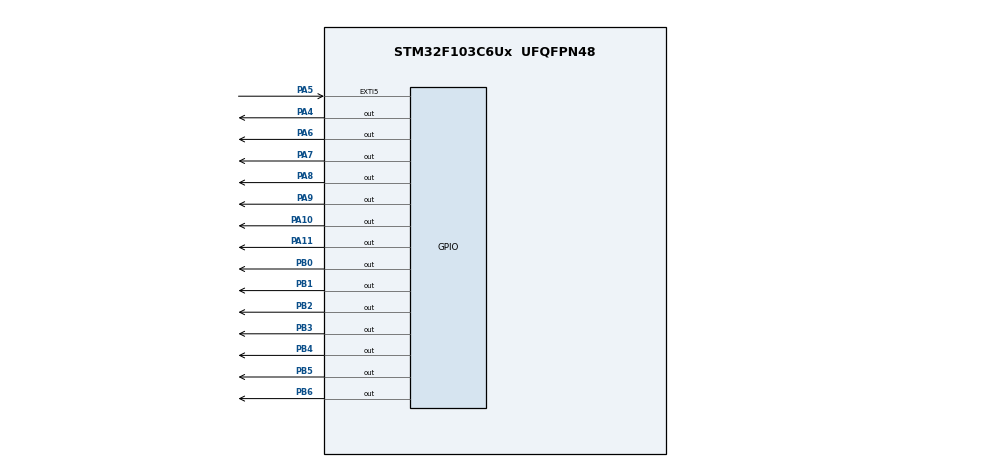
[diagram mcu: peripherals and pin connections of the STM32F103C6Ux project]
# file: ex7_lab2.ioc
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Mcu.Family=STM32F1
Mcu.Name=STM32F103C6Ux
Mcu.Package=UFQFPN48
NVIC.PriorityGroup=NVIC_PRIORITYGROUP_4
NVIC.TIM2_IRQn=true\:0\:0\:false\:false\:true\:true\:true
PA10.Signal=GPIO_Output
PA11.Signal=GPIO_Output
PA4.Signal=GPIO_Output
PA5.Signal=GPXTI5
PA6.Signal=GPIO_Output
PA7.Signal=GPIO_Output
PA8.Signal=GPIO_Output
PA9.Signal=GPIO_Output
PB0.Signal=GPIO_Output
PB1.Signal=GPIO_Output
PB2.Signal=GPIO_Output
PB3.Signal=GPIO_Output
PB4.Signal=GPIO_Output
PB5.Signal=GPIO_Output
PB6.Signal=GPIO_Output
ProjectManager.HeapSize=0x200
ProjectManager.StackSize=0x400
ProjectManager.TargetToolchain=STM32CubeIDE
RCC.APB1Freq_Value=8000000
RCC.APB2Freq_Value=8000000
TIM2.Period=9
TIM2.Prescaler=799
VP_SYS_VS_ND.Mode=No_Debug
VP_TIM2_VS_ClockSourceINT.Mode=Internal
board=custom

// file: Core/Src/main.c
/* USER CODE BEGIN Header */
/**
 ******************************************************************************
 * @file           : main.c
 * @brief          : Main program body
 ******************************************************************************
 * @attention
 *
 * <h2><center>&copy; Copyright (c) 2024 STMicroelectronics.
 * All rights reserved.</center></h2>
 *
 * This software component is licensed by ST under BSD 3-Clause license,
 * the "License"; You may not use this file except in compliance with the
 * License. You may obtain a copy of the License at:
 *                        opensource.org/licenses/BSD-3-Clause
 *
 ******************************************************************************
 */
/* USER CODE END Header */
#include "main.h"
int clockCounter = 50;
int dotCounter = 10;
int indexLed = 0;
int maxLedNum = 6;
int led_buffer[6];
int hour = 15, minute = 50, second = 0;
int zero[6] = { 0, 1, 2, 3, 4, 5 };
int one[2] = { 1, 2 };
int two[5] = { 0, 1, 6, 4, 3 };
int three[5] = { 0, 1, 6, 2, 3 };
int four[4] = { 5, 6, 1, 2 };
int five[5] = { 0, 5, 6, 2, 3 };
int six[6] = { 0, 5, 6, 2, 3, 4 };
int seven[3] = { 0, 1, 2 };
int eight[7] = { 0, 1, 2, 3, 4, 5, 6 };
int nine[6] = { 0, 1, 2, 3, 5, 6 };

int timer0_counter = 1;
int timer1_counter = 0;
int timer2_counter = 0;
int timer0_flag = 0;
int timer1_flag = 0;
int timer2_flag = 0;
int TIMER_CYCLE = 10;
void setTimer0(int duration) {
	timer0_counter = duration / TIMER_CYCLE;
	timer0_flag = 0;
}
void setTimer1(int duration) {
	timer1_counter = duration / TIMER_CYCLE;
	timer1_flag = 0;
}
void setTimer2(int duration) {
	timer2_counter = duration / TIMER_CYCLE;
	timer2_flag = 0;
}
void timer0_run() {
	if (timer0_counter > 0) {
		timer0_counter--;
		if (timer0_counter == 0) {
			timer0_flag = 1;
		}
	}

}
void timer1_run() {

	if (timer1_counter > 0) {
		timer1_counter--;
		if (timer1_counter == 0) {
			timer1_flag = 1;
		}
	}

}
void timer2_run() {

	if (timer2_counter > 0) {
		timer2_counter--;
		if (timer2_counter == 0) {
			timer2_flag = 1;
		}
	}
}
void display_7_SEG(int num) {
	for (int a = 0; a < 7; a++) {
		uint16_t b = a;
		HAL_GPIO_WritePin(GPIOB, (uint16_t) (1 << b), GPIO_PIN_SET);

	}
	switch (num) {

	case 0:
		for (int a = 0; a < sizeof(zero) / sizeof(*zero); a++) {
			uint16_t b = zero[a];
			HAL_GPIO_WritePin(GPIOB, (uint16_t) (1 << b), GPIO_PIN_RESET);
		}
		break;
	case 1:
		for (int a = 0; a < sizeof(one) / sizeof(*one); a++) {
			uint16_t b = one[a];
			HAL_GPIO_WritePin(GPIOB, (uint16_t) (1 << b), GPIO_PIN_RESET);
		}
		break;
	case 2:
		for (int a = 0; a < sizeof(two) / sizeof(*two); a++) {
			uint16_t b = two[a];
			HAL_GPIO_WritePin(GPIOB, (uint16_t) (1 << b), GPIO_PIN_RESET);
		}
		break;
	case 3:
		for (int a = 0; a < sizeof(three) / sizeof(*three); a++) {
			uint16_t b = three[a];
			HAL_GPIO_WritePin(GPIOB, (uint16_t) (1 << b), GPIO_PIN_RESET);
		}
		break;
	case 4:
		for (int a = 0; a < sizeof(four) / sizeof(*four); a++) {
			uint16_t b = four[a];
			HAL_GPIO_WritePin(GPIOB, (uint16_t) (1 << b), GPIO_PIN_RESET);
		}
		break;
	case 5:
		for (int a = 0; a < sizeof(five) / sizeof(*five); a++) {
			uint16_t b = five[a];
			HAL_GPIO_WritePin(GPIOB, (uint16_t) (1 << b), GPIO_PIN_RESET);
		}
		break;
	case 6:
		for (int a = 0; a < sizeof(six) / sizeof(*six); a++) {
			uint16_t b = six[a];
			HAL_GPIO_WritePin(GPIOB, (uint16_t) (1 << b), GPIO_PIN_RESET);
		}
		break;
	case 7:
		for (int a = 0; a < sizeof(seven) / sizeof(*seven); a++) {
			uint16_t b = seven[a];
			HAL_GPIO_WritePin(GPIOB, (uint16_t) (1 << b), GPIO_PIN_RESET);
		}
		break;
	case 8:
		for (int a = 0; a < sizeof(eight) / sizeof(*eight); a++) {
			uint16_t b = eight[a];
			HAL_GPIO_WritePin(GPIOB, (uint16_t) (1 << b), GPIO_PIN_RESET);
		}
		break;
	case 9:
		for (int a = 0; a < sizeof(nine) / sizeof(*nine); a++) {
			uint16_t b = nine[a];
			HAL_GPIO_WritePin(GPIOB, (uint16_t) (1 << b), GPIO_PIN_RESET);
		}
		break;

	}

}
void update7SEG(int index) {
	switch (index) {
	case 0:
		HAL_GPIO_WritePin(GPIOA, GPIO_PIN_6, GPIO_PIN_RESET);
		HAL_GPIO_WritePin(GPIOA,
		GPIO_PIN_7 | GPIO_PIN_8 | GPIO_PIN_9 | GPIO_PIN_10 | GPIO_PIN_11,
				GPIO_PIN_SET);
		display_7_SEG(led_buffer[0]);
		break;
	case 1:
		HAL_GPIO_WritePin(GPIOA, GPIO_PIN_7, GPIO_PIN_RESET);
		HAL_GPIO_WritePin(GPIOA,
		GPIO_PIN_6 | GPIO_PIN_8 | GPIO_PIN_9 | GPIO_PIN_10 | GPIO_PIN_11,
				GPIO_PIN_SET);
		display_7_SEG(led_buffer[1]);
		break;
	case 2:
		HAL_GPIO_WritePin(GPIOA, GPIO_PIN_8, GPIO_PIN_RESET);
		HAL_GPIO_WritePin(GPIOA,
		GPIO_PIN_6 | GPIO_PIN_7 | GPIO_PIN_9 | GPIO_PIN_10 | GPIO_PIN_11,
				GPIO_PIN_SET);
		display_7_SEG(led_buffer[2]);
		break;
	case 3:
		HAL_GPIO_WritePin(GPIOA, GPIO_PIN_9, GPIO_PIN_RESET);
		HAL_GPIO_WritePin(GPIOA,
		GPIO_PIN_6 | GPIO_PIN_7 | GPIO_PIN_8 | GPIO_PIN_10 | GPIO_PIN_11,
				GPIO_PIN_SET);
		display_7_SEG(led_buffer[3]);
		break;
	case 4:
		HAL_GPIO_WritePin(GPIOA, GPIO_PIN_10, GPIO_PIN_RESET);
		HAL_GPIO_WritePin(GPIOA,
		GPIO_PIN_6 | GPIO_PIN_7 | GPIO_PIN_8 | GPIO_PIN_9 | GPIO_PIN_11,
				GPIO_PIN_SET);
		display_7_SEG(led_buffer[4]);
		break;
	case 5:
		HAL_GPIO_WritePin(GPIOA, GPIO_PIN_11, GPIO_PIN_RESET);
		HAL_GPIO_WritePin(GPIOA,
		GPIO_PIN_6 | GPIO_PIN_7 | GPIO_PIN_8 | GPIO_PIN_9 | GPIO_PIN_10,
				GPIO_PIN_SET);
		display_7_SEG(led_buffer[5]);
		break;
	default:
		break;
	}
}
void HAL_TIM_PeriodElapsedCallback(TIM_HandleTypeDef *htim) {

	clockCounter--;
	timer0_run();
	timer1_run();
	timer2_run();

}
void updateClockBuffer() {

	led_buffer[0] = hour / 10;
	led_buffer[1] = hour % 10;
	led_buffer[2] = minute / 10;
	led_buffer[3] = minute % 10;
	led_buffer[4] = second / 10;
	led_buffer[5] = second % 10;

}

TIM_HandleTypeDef htim2;

void SystemClock_Config(void);
static void MX_GPIO_Init(void);
static void MX_TIM2_Init(void);

int main(void) {

	/* MCU Configuration--------------------------------------------------------*/

	/* Reset of all peripherals, Initializes the Flash interface and the Systick. */
	HAL_Init();

	/* Configure the system clock */
	SystemClock_Config();

	/* Initialize all configured peripherals */
	MX_GPIO_Init();
	MX_TIM2_Init();
	HAL_TIM_Base_Start_IT(&htim2);
	/* Infinite loop */
	/* USER CODE BEGIN WHILE */
	setTimer0(1000);
	setTimer1(1000);
	//setTimer2(0);
	while (1) {
		/* USER CODE END WHILE */
		if (timer0_flag == 1) {
			HAL_GPIO_TogglePin(GPIOA, GPIO_PIN_5);
			HAL_GPIO_TogglePin(GPIOA, GPIO_PIN_4);

			second++;
			if (second >= 60) {
				second = 0;
				minute++;
			}
			if (minute >= 60) {
				minute = 0;
				hour++;
			}
			if (hour >= 24) {
				hour = 0;
			}
			updateClockBuffer();
			setTimer0(10000);
		}
		if (timer1_flag == 1) {
			update7SEG(indexLed);
			clockCounter = 50;
			indexLed++;
			if (indexLed >= maxLedNum) {
				indexLed = 0;
			}
			setTimer1(1000);
		}

	}
}

void SystemClock_Config(void) {
	RCC_OscInitTypeDef RCC_OscInitStruct = { 0 };
	RCC_ClkInitTypeDef RCC_ClkInitStruct = { 0 };

	/** Initializes the RCC Oscillators according to the specified parameters
	 * in the RCC_OscInitTypeDef structure.
	 */
	RCC_OscInitStruct.OscillatorType = RCC_OSCILLATORTYPE_HSI;
	RCC_OscInitStruct.HSIState = RCC_HSI_ON;
	RCC_OscInitStruct.HSICalibrationValue = RCC_HSICALIBRATION_DEFAULT;
	RCC_OscInitStruct.PLL.PLLState = RCC_PLL_NONE;
	if (HAL_RCC_OscConfig(&RCC_OscInitStruct) != HAL_OK) {
		Error_Handler();
	}
	/** Initializes the CPU, AHB and APB buses clocks
	 */
	RCC_ClkInitStruct.ClockType = RCC_CLOCKTYPE_HCLK | RCC_CLOCKTYPE_SYSCLK
			| RCC_CLOCKTYPE_PCLK1 | RCC_CLOCKTYPE_PCLK2;
	RCC_ClkInitStruct.SYSCLKSource = RCC_SYSCLKSOURCE_HSI;
	RCC_ClkInitStruct.AHBCLKDivider = RCC_SYSCLK_DIV1;
	RCC_ClkInitStruct.APB1CLKDivider = RCC_HCLK_DIV1;
	RCC_ClkInitStruct.APB2CLKDivider = RCC_HCLK_DIV1;

	if (HAL_RCC_ClockConfig(&RCC_ClkInitStruct, FLASH_LATENCY_0) != HAL_OK) {
		Error_Handler();
	}
}

static void MX_TIM2_Init(void) {

	TIM_ClockConfigTypeDef sClockSourceConfig = { 0 };
	TIM_MasterConfigTypeDef sMasterConfig = { 0 };

	htim2.Instance = TIM2;
	htim2.Init.Prescaler = 799;
	htim2.Init.CounterMode = TIM_COUNTERMODE_UP;
	htim2.Init.Period = 9;
	htim2.Init.ClockDivision = TIM_CLOCKDIVISION_DIV1;
	htim2.Init.AutoReloadPreload = TIM_AUTORELOAD_PRELOAD_DISABLE;
	if (HAL_TIM_Base_Init(&htim2) != HAL_OK) {
		Error_Handler();
	}
	sClockSourceConfig.ClockSource = TIM_CLOCKSOURCE_INTERNAL;
	if (HAL_TIM_ConfigClockSource(&htim2, &sClockSourceConfig) != HAL_OK) {
		Error_Handler();
	}
	sMasterConfig.MasterOutputTrigger = TIM_TRGO_RESET;
	sMasterConfig.MasterSlaveMode = TIM_MASTERSLAVEMODE_DISABLE;
	if (HAL_TIMEx_MasterConfigSynchronization(&htim2, &sMasterConfig)
			!= HAL_OK) {
		Error_Handler();
	}

}

static void MX_GPIO_Init(void) {
	GPIO_InitTypeDef GPIO_InitStruct = { 0 };

	/* GPIO Ports Clock Enable */
	__HAL_RCC_GPIOA_CLK_ENABLE();
	__HAL_RCC_GPIOB_CLK_ENABLE();

	/*Configure GPIO pin Output Level */
	HAL_GPIO_WritePin(GPIOA,
			GPIO_PIN_4 | GPIO_PIN_6 | GPIO_PIN_7 | GPIO_PIN_8 | GPIO_PIN_9
					| GPIO_PIN_10 | GPIO_PIN_11, GPIO_PIN_RESET);

	/*Configure GPIO pin Output Level */
	HAL_GPIO_WritePin(GPIOB,
			GPIO_PIN_0 | GPIO_PIN_1 | GPIO_PIN_2 | GPIO_PIN_3 | GPIO_PIN_4
					| GPIO_PIN_5 | GPIO_PIN_6, GPIO_PIN_RESET);

	/*Configure GPIO pins : PA4 PA6 PA7 PA8
	 PA9 PA10 PA11 */
	GPIO_InitStruct.Pin = GPIO_PIN_4 | GPIO_PIN_6 | GPIO_PIN_7 | GPIO_PIN_8
			| GPIO_PIN_9 | GPIO_PIN_10 | GPIO_PIN_11;
	GPIO_InitStruct.Mode = GPIO_MODE_OUTPUT_PP;
	GPIO_InitStruct.Pull = GPIO_NOPULL;
	GPIO_InitStruct.Speed = GPIO_SPEED_FREQ_LOW;
	HAL_GPIO_Init(GPIOA, &GPIO_InitStruct);

	/*Configure GPIO pin : PA5 */
	GPIO_InitStruct.Pin = GPIO_PIN_5;
	GPIO_InitStruct.Mode = GPIO_MODE_IT_RISING;
	GPIO_InitStruct.Pull = GPIO_NOPULL;
	HAL_GPIO_Init(GPIOA, &GPIO_InitStruct);

	/*Configure GPIO pins : PB0 PB1 PB2 PB3
	 PB4 PB5 PB6 */
	GPIO_InitStruct.Pin = GPIO_PIN_0 | GPIO_PIN_1 | GPIO_PIN_2 | GPIO_PIN_3
			| GPIO_PIN_4 | GPIO_PIN_5 | GPIO_PIN_6;
	GPIO_InitStruct.Mode = GPIO_MODE_OUTPUT_PP;
	GPIO_InitStruct.Pull = GPIO_NOPULL;
	GPIO_InitStruct.Speed = GPIO_SPEED_FREQ_LOW;
	HAL_GPIO_Init(GPIOB, &GPIO_InitStruct);

}

void Error_Handler(void) {
	__disable_irq();
	while (1) {
	}
}

/************************ (C) COPYRIGHT STMicroelectronics *****END OF FILE****/
